VERSION ""

NS_ :

BS_:

BU_:

BO_ 1888 EMCU_STATUS_1: 4 Vector__XXX
 SG_ Uptime : 0|32@1+ (1,0) [0|4294970000] "" Vector__XXX

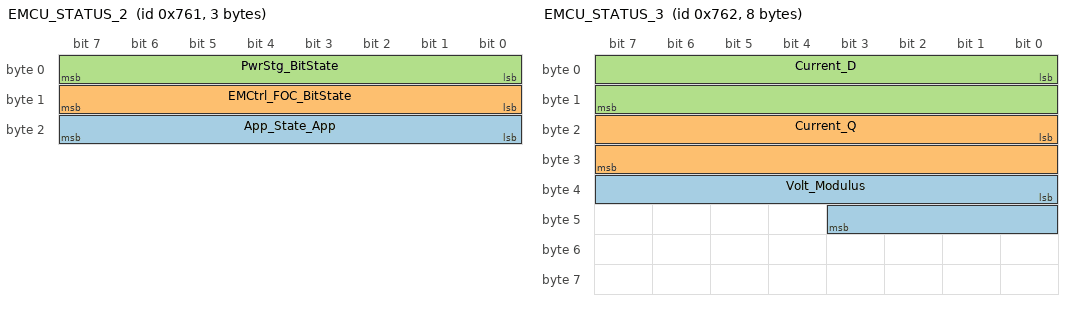
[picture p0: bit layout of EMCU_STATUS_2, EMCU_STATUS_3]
BO_ 1889 EMCU_STATUS_2: 3 Vector__XXX
 SG_ App_State_App : 16|8@1+ (1,0) [0|255] "" Vector__XXX
 SG_ EMCtrl_FOC_BitState : 8|8@1+ (1,0) [0|255] "" Vector__XXX
 SG_ PwrStg_BitState : 0|8@1+ (1,0) [0|255] "" Vector__XXX

BO_ 1890 EMCU_STATUS_3: 8 Vector__XXX
 SG_ Volt_Modulus : 32|12@1+ (1,0) [0|4095] "" Vector__XXX
 SG_ Current_Q : 16|16@1- (0.03125,0) [-1024|1023.97] "" Vector__XXX
 SG_ Current_D : 0|16@1- (0.03125,0) [-1024|1023.97] "" Vector__XXX

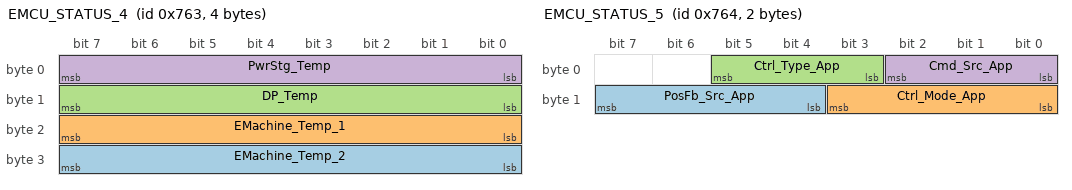
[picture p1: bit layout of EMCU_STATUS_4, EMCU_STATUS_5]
BO_ 1891 EMCU_STATUS_4: 4 Vector__XXX
 SG_ EMachine_Temp_2 : 24|8@1- (1,0) [-128|127] "" Vector__XXX
 SG_ EMachine_Temp_1 : 16|8@1- (1,0) [-128|127] "" Vector__XXX
 SG_ DP_Temp : 8|8@1- (1,0) [-128|127] "" Vector__XXX
 SG_ PwrStg_Temp : 0|8@1- (1,0) [-128|127] "" Vector__XXX

BO_ 1892 EMCU_STATUS_5: 2 Vector__XXX
 SG_ PosFb_Src_App : 12|4@1+ (1,0) [0|15] "" Vector__XXX
 SG_ Ctrl_Mode_App : 8|4@1+ (1,0) [0|15] "" Vector__XXX
 SG_ Ctrl_Type_App : 3|3@1+ (1,0) [0|7] "" Vector__XXX
 SG_ Cmd_Src_App : 0|3@1+ (1,0) [0|7] "" Vector__XXX

BO_ 1893 EMCU_STATUS_6: 2 Vector__XXX
 SG_ Dem : 0|16@1+ (1,0) [0|65535] "" Vector__XXX

BO_ 1632 EMCU_SETPOINT_1: 1 Vector__XXX
 SG_ App_State_Req : 0|8@1+ (1,0) [0|255] "" Vector__XXX

BO_ 1633 EMCU_SETPOINT_2: 4 Vector__XXX
 SG_ Current_Q_Req : 16|16@1- (0.03125,0) [-1024|1023.97] "" Vector__XXX
 SG_ Current_D_Req : 0|16@1- (0.03125,0) [-1024|1023.97] "" Vector__XXX

BO_ 1634 EMCU_SETPOINT_3: 2 Vector__XXX
 SG_ Torque_Req : 0|16@1- (1,0) [-32768|32767] "" Vector__XXX

CM_ SG_ 1888 Uptime "Control unit uptime in ms";
CM_ SG_ 1889 App_State_App "Application state";
CM_ SG_ 1889 EMCtrl_FOC_BitState "FOC controller status bitfield";
CM_ SG_ 1889 PwrStg_BitState "Power Stage Status bitfield";
CM_ SG_ 1890 Volt_Modulus "Voltage modulus";
CM_ SG_ 1890 Current_Q "Current feedback Q-axis";
CM_ SG_ 1890 Current_D "Current feedback D-axis";
CM_ SG_ 1891 EMachine_Temp_2 "Machine temperature";
CM_ SG_ 1891 EMachine_Temp_1 "Machine temperature";
CM_ SG_ 1891 DP_Temp "Digital platform temperature";
CM_ SG_ 1891 PwrStg_Temp "Power Stage tempereture";
CM_ SG_ 1892 PosFb_Src_App "Position Feedback source";
CM_ SG_ 1892 Ctrl_Mode_App "Control Mode";
CM_ SG_ 1892 Ctrl_Type_App "Control Type";
CM_ SG_ 1892 Cmd_Src_App "Comands source";
CM_ SG_ 1633 Current_Q_Req "Current Setpoint";
CM_ SG_ 1633 Current_D_Req "Current Setpoint";
CM_ SG_ 1634 Torque_Req "Torque Setponit";
